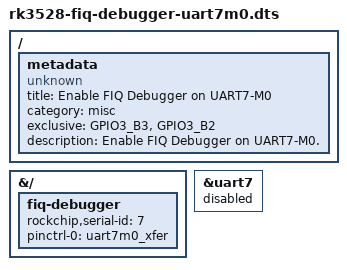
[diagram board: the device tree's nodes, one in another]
/dts-v1/;
/plugin/;

/ {
	metadata {
		title = "Enable FIQ Debugger on UART7-M0";
		compatible = "unknown";
		category = "misc";
		exclusive = "GPIO3_B3", "GPIO3_B2";
		description = "Enable FIQ Debugger on UART7-M0.";
	};
};

&{/} {
	fiq-debugger {
		status = "okay";
		rockchip,serial-id = <7>;
		pinctrl-names = "default";
		pinctrl-0 = <&uart7m0_xfer>;
	};
};

&uart7 {
	status = "disabled";
};
